# SAMA7G54D1GN2 register map
Vendor: Microchip Technology; Series: SAMA7G5; File version: 0
Registers are 32-bit, read-write, reset 0x0 unless marked. A register's access mark holds for its fields unless they carry their own. Offsets are from the block's base; [hi:lo] are bit positions; lines under a group give offsets from that group; {n}, {i} and the like mark numbered series; 'fields as' and 'values as' point back to an identical list.

## TC0 — Timer Counter
Base 0xE2814000; register names take the prefix TC_
Same registers: TC1 0xE0800000
{0x0+0x40*i} TC_CHANNEL[{i}] (i=0..2) group
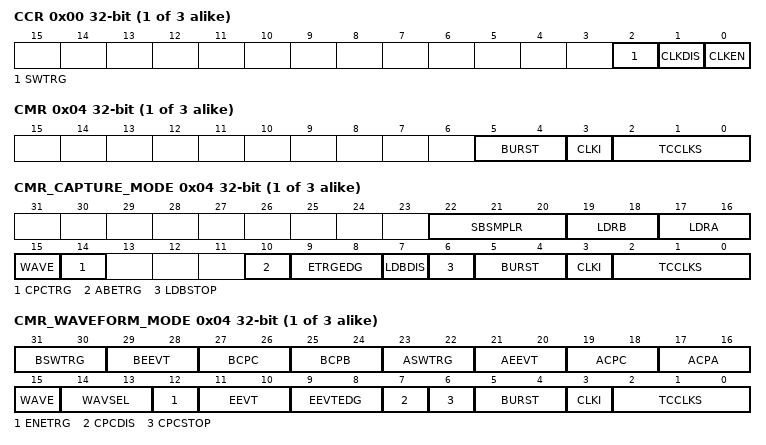
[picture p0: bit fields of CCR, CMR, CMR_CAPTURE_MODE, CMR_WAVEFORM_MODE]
  0x00 CCR wo — Channel Control Register
    [2] SWTRG — Software Trigger Command
      0=No effect; 1=A software trigger is performed: the counter is reset and the clock is started
    [1] CLKDIS — Counter Clock Disable Command
      0=No effect; 1=Disables the clock
    [0] CLKEN — Counter Clock Enable Command
      0=No effect; 1=Enables the clock if CLKDIS is not 1
  0x04 CMR — Channel Mode Register
    [5:4] BURST — Burst Signal Selection
      0=NONE (The clock is not gated by an external signal.); 1=XC0 (XC0 is ANDed with the selected clock.); 2=XC1 (XC1 is ANDed with the selected clock.); 3=XC2 (XC2 is ANDed with the selected clock.)
    [3] CLKI — Clock Invert
      0=Counter is incremented on rising edge of the clock; 1=Counter is incremented on falling edge of the clock
    [2:0] TCCLKS — Clock Selection
      0=TIMER_CLOCK1 (Clock selected: internal GCLK [TC_ID] clock signal (from PMC)); 1=TIMER_CLOCK2 (Clock selected: internal MCK0/8 clock signal (from PMC)); 2=TIMER_CLOCK3 (Clock selected: internal MCK0/32 clock signal (from PMC)); 3=TIMER_CLOCK4 (Clock selected: internal MCK0/128 clock signal (from PMC)); 4=TIMER_CLOCK5 (Clock selected: internal TD_SLCK clock signal (from PMC)); 5=XC0 (Clock selected: XC0); 6=XC1 (Clock selected: XC1); 7=XC2 (Clock selected: XC2)
  0x04 CMR_CAPTURE_MODE (alternate view of CMR) — Channel Mode Register
    [22:20] SBSMPLR — Loading Edge Subsampling Ratio
      0=ONE (Load a Capture register each selected edge); 1=HALF (Load a Capture register every 2 selected edges); 2=FOURTH (Load a Capture register every 4 selected edges); 3=EIGHTH (Load a Capture register every 8 selected edges); 4=SIXTEENTH (Load a Capture register every 16 selected edges)
    [19:18] LDRB — RB Loading Edge Selection
      0=NONE; 1=RISING (Rising edge of TIOAx); 2=FALLING (Falling edge of TIOAx); 3=EDGE (Each edge of TIOAx)
    [17:16] LDRA — RA Loading Edge Selection
      values as LDRB
    [15] WAVE — Waveform Mode
      0=Capture mode is enabled; 1=Capture mode is disabled (Waveform mode is enabled)
    [14] CPCTRG — RC Compare Trigger Enable
      0=RC Compare has no effect on the counter and its clock; 1=RC Compare resets the counter and starts the counter clock
    [10] ABETRG — TIOAx or TIOBx External Trigger Selection
      0=TIOBx is used as an external trigger; 1=TIOAx is used as an external trigger
    [9:8] ETRGEDG — External Trigger Edge Selection
      0=NONE (The clock is not gated by an external signal.); 1=RISING (Rising edge); 2=FALLING (Falling edge); 3=EDGE (Each edge)
    [7] LDBDIS — Counter Clock Disable with RB Loading
      0=Counter clock is not disabled when RB loading occurs; 1=Counter clock is disabled when RB loading occurs
    [6] LDBSTOP — Counter Clock Stopped with RB Loading
      0=Counter clock is not stopped when RB loading occurs; 1=Counter clock is stopped when RB loading occurs
    [5:4] BURST — Burst Signal Selection
      values as TC_CHANNEL[0].CMR.BURST
    [3] CLKI — Clock Invert
      values as TC_CHANNEL[0].CMR.CLKI
    [2:0] TCCLKS — Clock Selection
      values as TC_CHANNEL[0].CMR.TCCLKS
  0x04 CMR_WAVEFORM_MODE (alternate view of CMR) — Channel Mode Register
    [31:30] BSWTRG — Software Trigger Effect on TIOBx
      0=NONE; 1=SET; 2=CLEAR; 3=TOGGLE
    [29:28] BEEVT — External Event Effect on TIOBx
      0=NONE; 1=SET; 2=CLEAR; 3=TOGGLE
    [27:26] BCPC — RC Compare Effect on TIOBx
      0=NONE; 1=SET; 2=CLEAR; 3=TOGGLE
    [25:24] BCPB — RB Compare Effect on TIOBx
      0=NONE; 1=SET; 2=CLEAR; 3=TOGGLE
    [23:22] ASWTRG — Software Trigger Effect on TIOAx
      0=NONE; 1=SET; 2=CLEAR; 3=TOGGLE
    [21:20] AEEVT — External Event Effect on TIOAx
      0=NONE; 1=SET; 2=CLEAR; 3=TOGGLE
    [19:18] ACPC — RC Compare Effect on TIOAx
      0=NONE; 1=SET; 2=CLEAR; 3=TOGGLE
    [17:16] ACPA — RA Compare Effect on TIOAx
      0=NONE; 1=SET; 2=CLEAR; 3=TOGGLE
    [15] WAVE — Waveform Mode
      0=Waveform mode is disabled (Capture mode is enabled); 1=Waveform mode is enabled
    [14:13] WAVSEL — Waveform Selection
      0=UP (UP mode without automatic trigger on RC Compare); 1=UPDOWN (UPDOWN mode without automatic trigger on RC Compare); 2=UP_RC (UP mode with automatic trigger on RC Compare); 3=UPDOWN_RC (UPDOWN mode with automatic trigger on RC Compare)
    [12] ENETRG — External Event Trigger Enable
      0=The external event has no effect on the counter and its clock; 1=The external event resets the counter and starts the counter clock
    [11:10] EEVT — External Event Selection
      0=TIOB; 1=XC0; 2=XC1; 3=XC2
    [9:8] EEVTEDG — External Event Edge Selection
      0=NONE; 1=RISING (Rising edge); 2=FALLING (Falling edge); 3=EDGE (Each edge)
    [7] CPCDIS — Counter Clock Disable with RC Compare
      0=Counter clock is not disabled when counter reaches RC; 1=Counter clock is disabled when counter reaches RC
    [6] CPCSTOP — Counter Clock Stopped with RC Compare
      0=Counter clock is not stopped when counter reaches RC; 1=Counter clock is stopped when counter reaches RC
    [5:4] BURST — Burst Signal Selection
      values as TC_CHANNEL[0].CMR.BURST
    [3] CLKI — Clock Invert
      values as TC_CHANNEL[0].CMR.CLKI
    [2:0] TCCLKS — Clock Selection
      values as TC_CHANNEL[0].CMR.TCCLKS
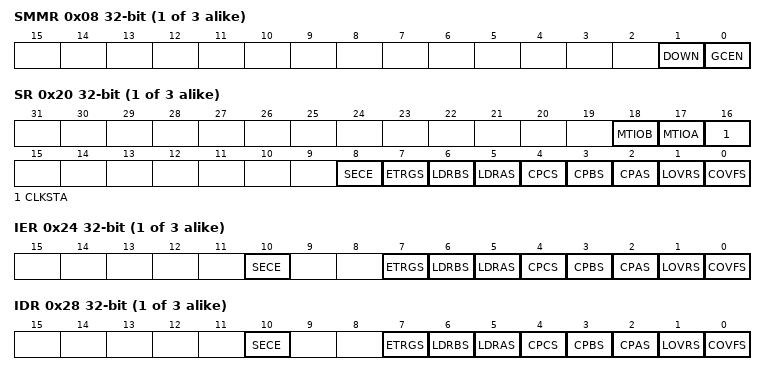
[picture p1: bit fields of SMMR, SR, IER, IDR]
  0x08 SMMR — Stepper Motor Mode Register
    [1] DOWN — Down Count
      0=Up counter; 1=Down counter
    [0] GCEN — Gray Count Enable
      0=TIOAx [x=0..2] and TIOBx [x=0..2] are driven by internal counter of channel x; 1=TIOAx [x=0..2] and TIOBx [x=0..2] are driven by a 2-bit Gray counter
  0x0C RAB ro — Register AB
    [31:0] RAB — Register A or Register B
  0x10 CV ro — Counter Value
  0x14 RA — Register A
  0x18 RB — Register B
  0x1C RC — Register C
  0x20 SR ro — Interrupt Status Register
    [18] MTIOB — TIOBx Mirror
      0=TIOBx is low. If TC_CMRx.WAVE = 0, TIOBx pin is low. If TC_CMRx.WAVE = 1, TIOBx is driven low.; 1=TIOBx is high. If TC_CMRx.WAVE = 0, TIOBx pin is high. If TC_CMRx.WAVE = 1, TIOBx is driven high.
    [17] MTIOA — TIOAx Mirror
      0=TIOAx is low. If TC_CMRx.WAVE = 0, TIOAx pin is low. If TC_CMRx.WAVE = 1, TIOAx is driven low.; 1=TIOAx is high. If TC_CMRx.WAVE = 0, TIOAx pin is high. If TC_CMRx.WAVE = 1, TIOAx is driven high.
    [16] CLKSTA — Clock Enabling Status
      0=Clock is disabled; 1=Clock is enabled
    [8] SECE — Security and/or Safety Event (cleared on read)
      0=No security or safety event occurred; 1=One or more safety or security event occurred since the last read of TC_SRx. For details on the event, refer to TC_SSRx.
    [7] ETRGS — External Trigger Status (cleared on read)
      0=External trigger has not occurred since the last read of the Status register; 1=External trigger has occurred since the last read of the Status register
    [6] LDRBS — RB Loading Status (cleared on read)
      0=RB Load has not occurred since the last read of the Status register or TC_CMRx.WAVE = 1; 1=RB Load has occurred since the last read of the Status register, if TC_CMRx.WAVE = 0
    [5] LDRAS — RA Loading Status (cleared on read)
      0=RA Load has not occurred since the last read of the Status register or TC_CMRx.WAVE = 1; 1=RA Load has occurred since the last read of the Status register, if TC_CMRx.WAVE = 0
    [4] CPCS — RC Compare Status (cleared on read)
      0=RC Compare has not occurred since the last read of the Status register; 1=RC Compare has occurred since the last read of the Status register
    [3] CPBS — RB Compare Status (cleared on read)
      0=RB Compare has not occurred since the last read of the Status register or TC_CMRx.WAVE = 0; 1=RB Compare has occurred since the last read of the Status register, if TC_CMRx.WAVE = 1
    [2] CPAS — RA Compare Status (cleared on read)
      0=RA Compare has not occurred since the last read of the Status register or TC_CMRx.WAVE = 0; 1=RA Compare has occurred since the last read of the Status register, if TC_CMRx.WAVE = 1
    [1] LOVRS — Load Overrun Status (cleared on read)
      0=Load overrun has not occurred since the last read of the Status register or TC_CMRx.WAVE = 1; 1=RA or RB have been loaded at least twice without any read of the corresponding register since the last read of the Status register, if TC_CMRx.WAVE = 0
    [0] COVFS — Counter Overflow Status (cleared on read)
      0=No counter overflow has occurred since the last read of the Status register; 1=A counter overflow has occurred since the last read of the Status register
  0x24 IER wo — Interrupt Enable Register
    [10] SECE — Security and/or Safety Event Interrupt Enable
    [7] ETRGS — External Trigger
    [6] LDRBS — RB Loading
    [5] LDRAS — RA Loading
    [4] CPCS — RC Compare
    [3] CPBS — RB Compare
    [2] CPAS — RA Compare
    [1] LOVRS — Load Overrun
    [0] COVFS — Counter Overflow
  0x28 IDR wo — Interrupt Disable Register
    [10] SECE — Security and/or Safety Event Interrupt Disable
    [7] ETRGS — External Trigger
    [6] LDRBS — RB Loading
    [5] LDRAS — RA Loading
    [4] CPCS — RC Compare
    [3] CPBS — RB Compare
    [2] CPAS — RA Compare
    [1] LOVRS — Load Overrun
    [0] COVFS — Counter Overflow
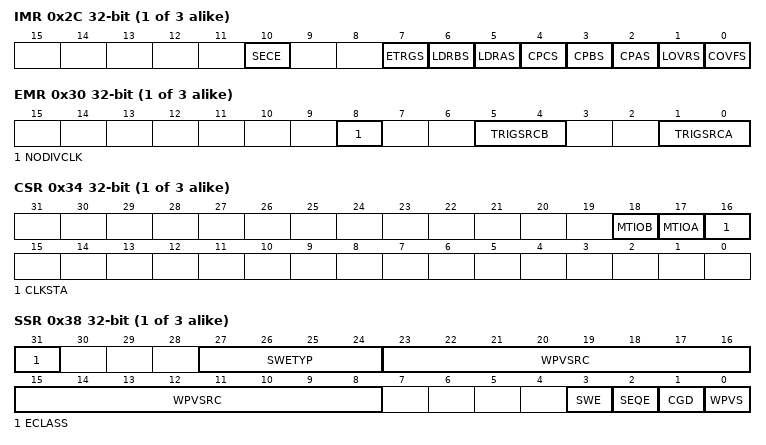
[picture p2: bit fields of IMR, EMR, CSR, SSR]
  0x2C IMR ro — Interrupt Mask Register
    [10] SECE — Security and/or Safety Event Interrupt Mask
    [7] ETRGS — External Trigger
    [6] LDRBS — RB Loading
    [5] LDRAS — RA Loading
    [4] CPCS — RC Compare
    [3] CPBS — RB Compare
    [2] CPAS — RA Compare
    [1] LOVRS — Load Overrun
    [0] COVFS — Counter Overflow
  0x30 EMR — Extended Mode Register
    [8] NODIVCLK — No Divided Clock
      0=The selected clock is defined by field TCCLKS in TC_CMRx; 1=The selected clock is peripheral clock and TCCLKS field (TC_CMRx) has no effect
    [5:4] TRIGSRCB — Trigger Source for Input B
      0=EXTERNAL_TIOBx (The trigger/capture input B is driven by external pin TIOBx); 1=PWMx (For all channels: The trigger/capture input B is driven internally by the comparator output (see Figure 7-17) of the PWMx.)
    [1:0] TRIGSRCA — Trigger Source for Input A
      0=EXTERNAL_TIOAx (The trigger/capture input A is driven by external pin TIOAx); 1=PWMx (For TC0, TC1.TIOB0, TC1.TIOB2: The trigger/capture input A is driven internally by PWMx. For TC1.TIOB1: The trigger/capture input A is driven internally by the GTSUCOMP signal of the Ethernet MAC (GMAC).)
  0x34 CSR ro — Channel Status Register
    [18] MTIOB — TIOBx Mirror
      0=TIOBx is low. If TC_CMRx.WAVE = 0, TIOBx is low. If TC_CMRx.WAVE = 1, TIOBx is driven low.; 1=TIOBx is high. If TC_CMRx.WAVE = 0, TIOBx is high. If TC_CMRx.WAVE = 1, TIOBx is driven high.
    [17] MTIOA — TIOAx Mirror
      0=TIOAx is low. If TC_CMRx.WAVE = 0, TIOAx is low. If TC_CMRx.WAVE = 1, TIOAx is driven low.; 1=TIOAx is high. If TC_CMRx.WAVE = 0, TIOAx is high. If TC_CMRx.WAVE = 1, TIOAx is driven high.
    [16] CLKSTA — Clock Enabling Status
      0=Clock is disabled; 1=Clock is enabled
  0x38 SSR ro — Safety Status Register
    [31] ECLASS — Software Error Class
      0=WARNING (An abnormal access that does not have any impact.); 1=ERROR (An abnormal access that may have an impact.)
    [27:24] SWETYP — Software Error Type (cleared on read)
      0=READ_WO (TC Channel x is enabled and a write-only register has been read (Warning).); 1=WRITE_RO (TC Channel x is enabled and a write access has been performed on a read-only register (Warning).); 2=UNDEF_RW (Access to an undefined address of the TC (Warning).); 3=W_RARB_CAPT (TC_RAx or TC_RBx are written while channel is enabled and configured in capture mode (Error).)
    [23:8] WPVSRC — Write Protection Violation Source (cleared on read)
    [3] SWE — Software Control Error (cleared on read)
      0=No software error has occurred since the last read of TC_SSRx; 1=A software error has occurred since the last read of TC_SSRx. The field SWETYP details the type of software error encountered.
    [2] SEQE — Internal Sequencer Error (cleared on read)
      0=No internal counter error has occurred since the last read of TC_SSRx. In normal operating conditions, SEQE is cleared.; 1=An internal counter error has occurred since the last read of TC_SSRx. This flag can be set only under abnormal operating conditions resulting in clock glitch, etc. The detection is enabled if TC_CSRx.CLKSTA=1, TC_CMRx.WAVE=1, TC_CMRx.CPCTRG=1 and flag is set if TC_CVx > TC_RCx.
    [1] CGD — Clock Glitch Detected (cleared on read)
      0=The clock monitoring has not been corrupted since the last read of TC_SSRx; 1=The clock monitoring has been corrupted since the last read of TC_SSRx. This flag can be set under abnormal operating conditions.
    [0] WPVS — Write Protection Violation Status (cleared on read)
      0=No write protection violation has occurred since the last read of TC_SSRx; 1=A write protection violation has occurred since the last read of TC_SSRx. If this violation is an unauthorized attempt to write a protected register, the associated violation is reported into field WPVSRC.
0xC0 BCR wo — Block Control Register
  [0] SYNC — Synchro Command
    0=No effect; 1=Asserts the SYNC signal which generates a software trigger simultaneously for each of the channels
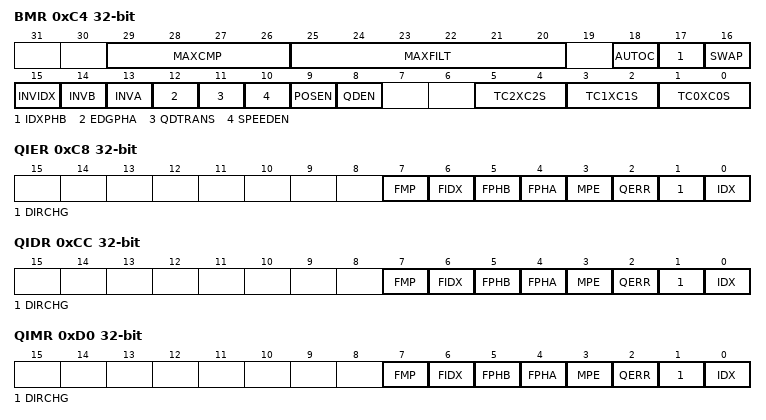
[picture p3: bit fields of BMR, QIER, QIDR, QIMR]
0xC4 BMR — Block Mode Register
  [29:26] MAXCMP — Maximum Consecutive Missing Pulses
    0=The flag MPE in TC_QISR never rises
  [25:20] MAXFILT — Maximum Filter
  [18] AUTOC — AutoCorrection of Missing Pulses
    0=DISABLED (The detection and autocorrection function is disabled.); 1=ENABLED (The detection and autocorrection function is enabled.)
  [17] IDXPHB — Index Pin is PHB Pin
    0=IDX pin of the rotary sensor must drive TIOA1; 1=IDX pin of the rotary sensor must drive TIOB0
  [16] SWAP — Swap PHA and PHB
    0=No swap between PHA and PHB; 1=Swap PHA and PHB internally, prior to driving the QDEC
  [15] INVIDX — Inverted Index
    0=IDX (TIOA1) is directly driving the QDEC; 1=IDX is inverted before driving the QDEC
  [14] INVB — Inverted PHB
    0=PHB (TIOB0) is directly driving the QDEC; 1=PHB is inverted before driving the QDEC
  [13] INVA — Inverted PHA
    0=PHA (TIOA0) is directly driving the QDEC; 1=PHA is inverted before driving the QDEC
  [12] EDGPHA — Edge on PHA Count Mode
    0=Edges are detected on PHA only; 1=Edges are detected on both PHA and PHB
  [11] QDTRANS — Quadrature Decoding Transparent
    0=Full quadrature decoding logic is active (direction change detected); 1=Quadrature decoding logic is inactive (direction change inactive) but input filtering and edge detection are performed
  [10] SPEEDEN — Speed Enabled
    0=Disabled; 1=Enables the speed measure on channel 0, the time base being provided by channel 2
  [9] POSEN — Position Enabled
    0=Disable position; 1=Enables the position measure on channel 0 and 1
  [8] QDEN — Quadrature Decoder Enabled
    0=Disabled; 1=Enables the QDEC (filter, edge detection and quadrature decoding)
  [5:4] TC2XC2S — External Clock Signal 2 (XC2) Selection
    0=TCLK2 (Signal connected to XC2: TCLK2); 2=TIOA0 (Signal connected to XC2: internal TIOA0 for chaining); 3=TIOA1 (Signal connected to XC2: internal TIOA1 for chaining)
  [3:2] TC1XC1S — External Clock Signal 1 (XC1) Selection
    0=TCLK1 (Signal connected to XC1: TCLK1); 2=TIOA0 (Signal connected to XC1: internal TIOA0 for chaining); 3=TIOA2 (Signal connected to XC1: internal TIOA2 for chaining)
  [1:0] TC0XC0S — External Clock Signal 0 (XC0) Selection
    0=TCLK0 (Signal connected to XC0: TCLK0); 2=TIOA1 (Signal connected to XC0: internal TIOA1 for chaining); 3=TIOA2 (Signal connected to XC0: internal TIOA2 for chaining)
0xC8 QIER wo — QDEC Interrupt Enable Register
  [7] FMP — Filtered Missing Pulse
    0=No effect; 1=Enables the interrupt when phase A or phase B has a corrected missing pulse
  [6] FIDX — Filtered Index Line
    0=No effect; 1=Enables the interrupt when index line has a filtered contamination
  [5] FPHB — Filtered Phase B Line
    0=No effect; 1=Enables the interrupt when phase B line has a filtered contamination
  [4] FPHA — Filtered Phase A Line
    0=No effect; 1=Enables the interrupt when phase A line has a filtered contamination
  [3] MPE — Consecutive Missing Pulse Error
    0=No effect; 1=Enables the interrupt when an occurrence of MAXCMP consecutive missing pulses is detected
  [2] QERR — Quadrature Error
    0=No effect; 1=Enables the interrupt when a quadrature error occurs on PHA, PHB
  [1] DIRCHG — Direction Change
    0=No effect; 1=Enables the interrupt when a change on rotation direction is detected
  [0] IDX — Index
    0=No effect; 1=Enables the interrupt when a rising edge occurs on IDX input
0xCC QIDR wo — QDEC Interrupt Disable Register
  [7] FMP — Filtered Missing Pulse
    0=No effect; 1=Disables the interrupt when phase A or phase B has a corrected missing pulse
  [6] FIDX — Filtered Index Line
    0=No effect; 1=Disables the interrupt when index line has a filtered contamination
  [5] FPHB — Filtered Phase B Line
    0=No effect; 1=Disables the interrupt when phase B line has a filtered contamination
  [4] FPHA — Filtered Phase A Line
    0=No effect; 1=Disables the interrupt when phase A line has a filtered contamination
  [3] MPE — Consecutive Missing Pulse Error
    0=No effect; 1=Disables the interrupt when an occurrence of MAXCMP consecutive missing pulses has been detected
  [2] QERR — Quadrature Error
    0=No effect; 1=Disables the interrupt when a quadrature error occurs on PHA, PHB
  [1] DIRCHG — Direction Change
    0=No effect; 1=Disables the interrupt when a change on rotation direction is detected
  [0] IDX — Index
    0=No effect; 1=Disables the interrupt when a rising edge occurs on IDX input
0xD0 QIMR ro — QDEC Interrupt Mask Register
  [7] FMP — Filtered Missing Pulse
    0=The interrupt on auto-corrected missing pulse is disabled; 1=The interrupt on auto-corrected missing pulse is enabled
  [6] FIDX — Filtered Index Line
    0=The interrupt on index line filtered contamination is disabled; 1=The interrupt on index line filtered contamination is enabled
  [5] FPHB — Filtered Phase B Line
    0=The interrupt on phase B line filtered contamination is disabled; 1=The interrupt on phase B line filtered contamination is enabled
  [4] FPHA — Filtered Phase A Line
    0=The interrupt on phase A line filtered contamination is disabled; 1=The interrupt on phase A line filtered contamination is enabled
  [3] MPE — Consecutive Missing Pulse Error
    0=The interrupt on the maximum number of consecutive missing pulses specified in MAXCMP is disabled; 1=The interrupt on the maximum number of consecutive missing pulses specified in MAXCMP is enabled
  [2] QERR — Quadrature Error
    0=The interrupt on quadrature error is disabled; 1=The interrupt on quadrature error is enabled
  [1] DIRCHG — Direction Change
    0=The interrupt on rotation direction change is disabled; 1=The interrupt on rotation direction change is enabled
  [0] IDX — Index
    0=The interrupt on IDX input is disabled; 1=The interrupt on IDX input is enabled
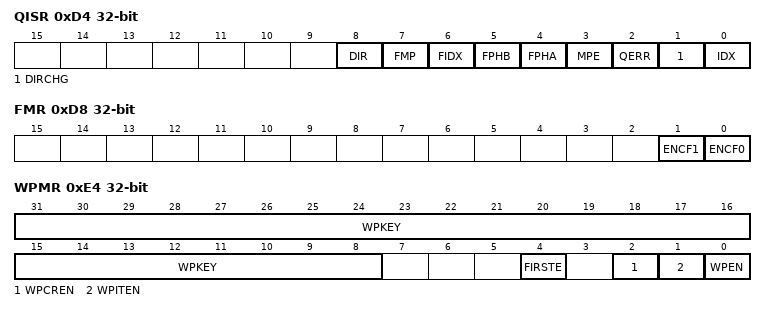
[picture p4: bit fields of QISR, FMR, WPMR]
0xD4 QISR ro — QDEC Interrupt Status Register
  [8] DIR — Direction
  [7] FMP — Filtered Missing Pulse
    0=No correction of missing pulse on phase A or B lines occurred since the last read of TC_QISR; 1=A correction of missing pulse on phase A or B lines occurred since the last read of TC_QISR
  [6] FIDX — Filtered Index Line
    0=No filtered contamination on index line since the last read of TC_QISR; 1=A contamination has been successfully on index line since the last read of TC_QISR
  [5] FPHB — Filtered Phase B Line
    0=No filtered contamination on phase B line since the last read of TC_QISR; 1=A contamination has been successfully on phase B line since the last read of TC_QISR
  [4] FPHA — Filtered Phase A Line
    0=No filtered contamination on phase A line since the last read of TC_QISR; 1=A contamination has been successfully on phase A line since the last read of TC_QISR
  [3] MPE — Consecutive Missing Pulse Error
    0=The number of consecutive missing pulses has not reached the maximum value specified in MAXCMP since the last read of TC_QISR; 1=An occurrence of MAXCMP consecutive missing pulses has been detected since the last read of TC_QISR
  [2] QERR — Quadrature Error
    0=No quadrature error since the last read of TC_QISR; 1=A quadrature error occurred since the last read of TC_QISR
  [1] DIRCHG — Direction Change
    0=No change on rotation direction since the last read of TC_QISR; 1=The rotation direction changed since the last read of TC_QISR
  [0] IDX — Index
    0=No Index input change since the last read of TC_QISR; 1=The IDX input has changed since the last read of TC_QISR
0xD8 FMR — Fault Mode Register
  [1] ENCF1 — Enable Compare Fault Channel 1
    0=Disables the FAULT output source (CPCS flag) from channel 1; 1=Enables the FAULT output source (CPCS flag) from channel 1
  [0] ENCF0 — Enable Compare Fault Channel 0
    0=Disables the FAULT output source (CPCS flag) from channel 0; 1=Enables the FAULT output source (CPCS flag) from channel 0
0xDC QSR ro — QDEC Status Register
  [8] DIR — Direction
0xE4 WPMR — Write Protection Mode Register
  [31:8] WPKEY — Write Protection Key
    0x54494D=PASSWD (Writing any other value in this field aborts the write operation of the WPEN bit. Always reads as 0.)
  [4] FIRSTE — First Error Report Enable
    0=The last write protection violation source is reported in TC_SSRx.WPVSRC and the last software control error type is reported in TC_SSRx.SWETYP. The TC_SRx.SECE flag is set at the first error occurrence within a series.; 1=Only the first write protection violation source is reported in TC_SSRx.WPVSRC and only the first software control error type is reported in TC_SSRx.SWETYP. The TC_SRx.SECE flag is set at the first error occurrence within a series.
  [2] WPCREN — Write Protection Control Enable
    0=Disables the write protection on control register if WPKEY corresponds to 0x54494D ('TIM' in ASCII); 1=Enables the write protection on control register if WPKEY corresponds to 0x54494D ('TIM' in ASCII)
  [1] WPITEN — Write Protection Interrupt Enable
    0=Disables the write protection on interrupt registers if WPKEY corresponds to 0x54494D ('TIM' in ASCII); 1=Enables the write protection on interrupt registers if WPKEY corresponds to 0x54494D ('TIM' in ASCII)
  [0] WPEN — Write Protection Enable
    0=Disables the write protection if WPKEY corresponds to 0x54494D ('TIM' in ASCII); 1=Enables the write protection if WPKEY corresponds to 0x54494D ('TIM' in ASCII)
